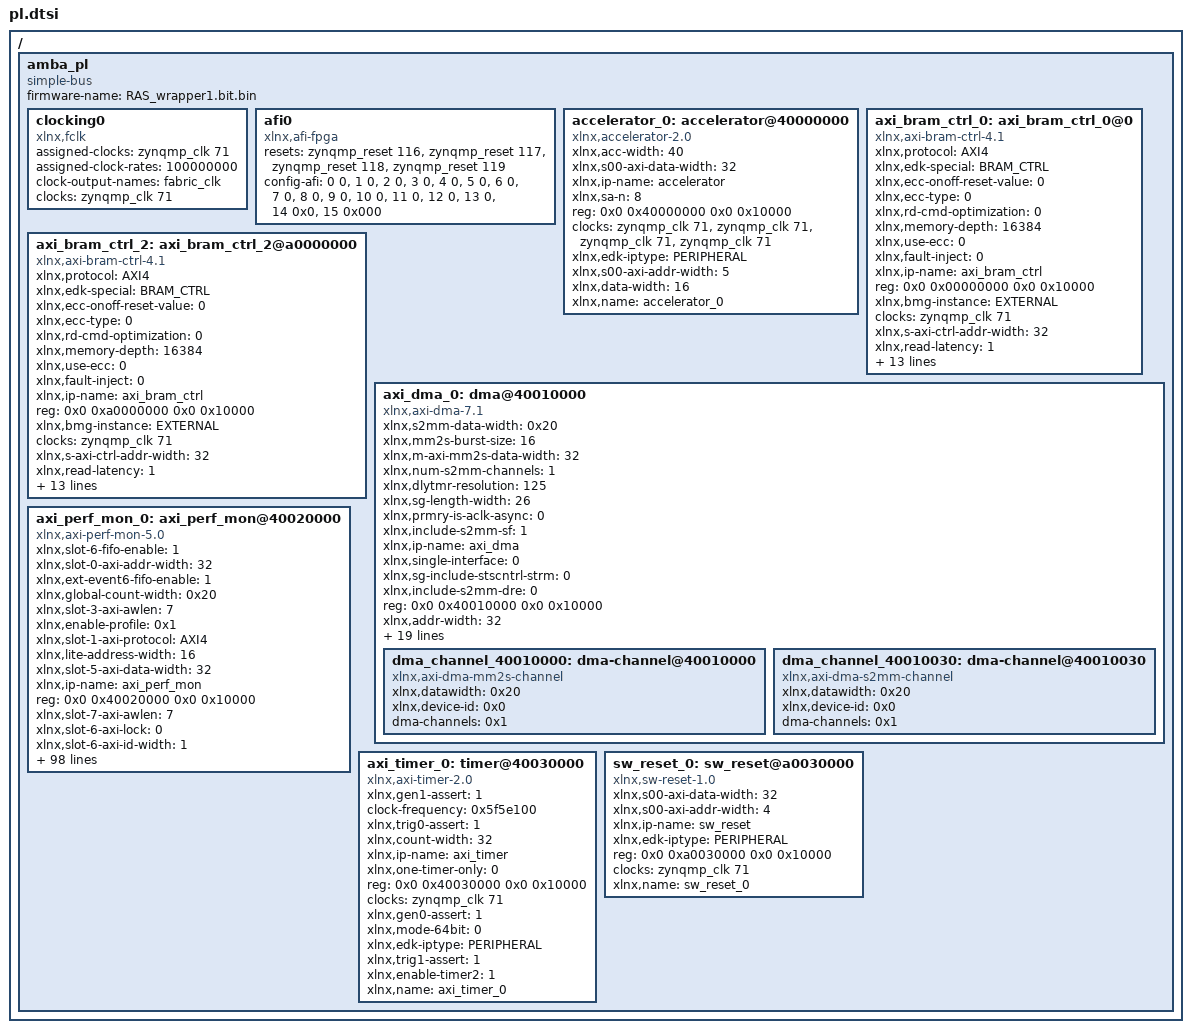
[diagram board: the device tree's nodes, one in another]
/ {
	amba_pl: amba_pl {
		ranges;
		compatible = "simple-bus";
		#address-cells = <2>;
		#size-cells = <2>;
		firmware-name = "RAS_wrapper1.bit.bin";
		clocking0: clocking0 {
			compatible = "xlnx,fclk";
			status = "okay";
			assigned-clocks = <&zynqmp_clk 71>;
			assigned-clock-rates = <100000000>;
			#clock-cells = <0>;
			clock-output-names = "fabric_clk";
			clocks = <&zynqmp_clk 71>;
		};
		afi0: afi0 {
			status = "okay";
			compatible = "xlnx,afi-fpga";
			resets = <&zynqmp_reset 116>, <&zynqmp_reset 117>, <&zynqmp_reset 118>, <&zynqmp_reset 119>;
			config-afi = < 0 0>, <1 0>, <2 0>, <3 0>, <4 0>, <5 0>, <6 0>, <7 0>, <8 0>, <9 0>, <10 0>, <11 0>, <12 0>, <13 0>, <14 0x0>, <15 0x000>;
		};
		accelerator_0: accelerator@40000000 {
			compatible = "xlnx,accelerator-2.0";
			xlnx,acc-width = <40>;
			xlnx,s00-axi-data-width = <32>;
			xlnx,ip-name = "accelerator";
			xlnx,sa-n = <8>;
			reg = <0x0 0x40000000 0x0 0x10000>;
			clocks = <&zynqmp_clk 71>, <&zynqmp_clk 71>, <&zynqmp_clk 71>, <&zynqmp_clk 71>;
			xlnx,edk-iptype = "PERIPHERAL";
			status = "okay";
			xlnx,s00-axi-addr-width = <5>;
			xlnx,data-width = <16>;
			clock-names = "m00_axis_aclk" , "m_axi_dma_aclk" , "s00_axi_aclk" , "s00_axis_aclk";
			xlnx,name = "accelerator_0";
		};
		axi_bram_ctrl_0: axi_bram_ctrl_0@0 {
			xlnx,protocol = "AXI4";
			xlnx,edk-special = "BRAM_CTRL";
			compatible = "xlnx,axi-bram-ctrl-4.1" , "xlnx,axi-bram-ctrl";
			xlnx,ecc-onoff-reset-value = <0>;
			xlnx,ecc-type = <0>;
			xlnx,rd-cmd-optimization = <0>;
			xlnx,memory-depth = <16384>;
			xlnx,use-ecc = <0>;
			xlnx,fault-inject = <0>;
			xlnx,ip-name = "axi_bram_ctrl";
			reg = <0x0 0x00000000 0x0 0x10000>;
			xlnx,bmg-instance = "EXTERNAL";
			clocks = <&zynqmp_clk 71>;
			xlnx,s-axi-ctrl-addr-width = <32>;
			xlnx,read-latency = <1>;
			xlnx,id-width = <0>;
			xlnx,s-axi-supports-narrow-burst = <0>;
			xlnx,supports-narrow-burst = <0>;
			xlnx,single-port-bram = <1>;
			xlnx,ecc = <0>;
			xlnx,edk-iptype = "PERIPHERAL";
			status = "okay";
			clock-names = "s_axi_aclk";
			xlnx,data-width = <32>;
			xlnx,bram-addr-width = <14>;
			xlnx,bram-inst-mode = "EXTERNAL";
			xlnx,s-axi-ctrl-data-width = <32>;
			xlnx,mem-depth = <16384>;
			xlnx,s-axi-id-width = <1>;
			xlnx,name = "axi_bram_ctrl_0";
		};
		axi_bram_ctrl_2: axi_bram_ctrl_2@a0000000 {
			xlnx,protocol = "AXI4";
			xlnx,edk-special = "BRAM_CTRL";
			compatible = "xlnx,axi-bram-ctrl-4.1" , "xlnx,axi-bram-ctrl";
			xlnx,ecc-onoff-reset-value = <0>;
			xlnx,ecc-type = <0>;
			xlnx,rd-cmd-optimization = <0>;
			xlnx,memory-depth = <16384>;
			xlnx,use-ecc = <0>;
			xlnx,fault-inject = <0>;
			xlnx,ip-name = "axi_bram_ctrl";
			reg = <0x0 0xa0000000 0x0 0x10000>;
			xlnx,bmg-instance = "EXTERNAL";
			clocks = <&zynqmp_clk 71>;
			xlnx,s-axi-ctrl-addr-width = <32>;
			xlnx,read-latency = <1>;
			xlnx,id-width = <0>;
			xlnx,s-axi-supports-narrow-burst = <0>;
			xlnx,supports-narrow-burst = <0>;
			xlnx,single-port-bram = <1>;
			xlnx,ecc = <0>;
			xlnx,edk-iptype = "PERIPHERAL";
			status = "okay";
			clock-names = "s_axi_aclk";
			xlnx,data-width = <32>;
			xlnx,bram-addr-width = <14>;
			xlnx,bram-inst-mode = "EXTERNAL";
			xlnx,s-axi-ctrl-data-width = <32>;
			xlnx,mem-depth = <16384>;
			xlnx,s-axi-id-width = <1>;
			xlnx,name = "axi_bram_ctrl_2";
		};
		axi_dma_0: dma@40010000 {
			compatible = "xlnx,axi-dma-7.1" , "xlnx,axi-dma-1.00.a";
			xlnx,s2mm-data-width = <0x20>;
			xlnx,mm2s-burst-size = <16>;
			xlnx,m-axi-mm2s-data-width = <32>;
			xlnx,num-s2mm-channels = <1>;
			xlnx,dlytmr-resolution = <125>;
			xlnx,sg-length-width = <26>;
			xlnx,prmry-is-aclk-async = <0>;
			xlnx,include-s2mm-sf = <1>;
			#dma-cells = <1>;
			xlnx,ip-name = "axi_dma";
			xlnx,single-interface = <0>;
			xlnx,sg-include-stscntrl-strm = <0>;
			xlnx,include-s2mm-dre = <0>;
			reg = <0x0 0x40010000 0x0 0x10000>;
			xlnx,addr-width = <32>;
			xlnx,include-s2mm = <1>;
			clocks = <&zynqmp_clk 71>, <&zynqmp_clk 71>, <&zynqmp_clk 71>;
			xlnx,s-axis-s2mm-tdata-width = <32>;
			xlnx,micro-dma = <0>;
			xlnx,increase-throughput = <0>;
			xlnx,mm2s-data-width = <0x20>;
			xlnx,addrwidth = <0x20>;
			xlnx,sg-use-stsapp-length = <0>;
			xlnx,m-axis-mm2s-tdata-width = <32>;
			xlnx,edk-iptype = "PERIPHERAL";
			xlnx,s2mm-burst-size = <16>;
			xlnx,m-axi-s2mm-data-width = <32>;
			xlnx,num-mm2s-channels = <1>;
			xlnx,enable-multi-channel = <0>;
			status = "okay";
			xlnx,include-mm2s-sf = <1>;
			clock-names = "m_axi_mm2s_aclk" , "m_axi_s2mm_aclk" , "s_axi_lite_aclk";
			xlnx,include-mm2s = <1>;
			xlnx,include-mm2s-dre = <0>;
			xlnx,name = "axi_dma_0";
			dma_channel_40010000: dma-channel@40010000 {
				xlnx,datawidth = <0x20>;
				xlnx,device-id = <0x0>;
				compatible = "xlnx,axi-dma-mm2s-channel";
				dma-channels = <0x1>;
			};
			dma_channel_40010030: dma-channel@40010030 {
				xlnx,datawidth = <0x20>;
				xlnx,device-id = <0x0>;
				compatible = "xlnx,axi-dma-s2mm-channel";
				dma-channels = <0x1>;
			};
		};
		axi_perf_mon_0: axi_perf_mon@40020000 {
			xlnx,slot-6-fifo-enable = <1>;
			xlnx,slot-0-axi-addr-width = <32>;
			xlnx,ext-event6-fifo-enable = <1>;
			xlnx,global-count-width = <0x20>;
			xlnx,slot-3-axi-awlen = <7>;
			xlnx,enable-profile = <0x1>;
			xlnx,slot-1-axi-protocol = "AXI4";
			xlnx,lite-address-width = <16>;
			xlnx,slot-5-axi-data-width = <32>;
			xlnx,ip-name = "axi_perf_mon";
			reg = <0x0 0x40020000 0x0 0x10000>;
			xlnx,slot-7-axi-awlen = <7>;
			xlnx,slot-6-axi-lock = <0>;
			xlnx,slot-6-axi-id-width = <1>;
			xlnx,slot-4-axi-data-width = <32>;
			xlnx,num-monitor-slots = <0x2>;
			xlnx,reg-all-monitor-signals = <0>;
			xlnx,slot-3-axi-id-width = <1>;
			xlnx,fifo-axis-sync = <0>;
			xlnx,s-axi-id-width = <1>;
			xlnx,slot-7-axi-addr-width = <32>;
			xlnx,slot-0-axi-awlen = <7>;
			compatible = "xlnx,axi-perf-mon-5.0" , "xlnx,axi-perf-monitor";
			xlnx,slot-7-axi-lock = <0>;
			xlnx,slot-6-axi-protocol = "AXI4";
			xlnx,en-last-write-flag = <1>;
			xlnx,slot-0-axi-lock = <0>;
			xlnx,axi4lite-core-clk-async = <0>;
			xlnx,slot-3-axi-data-width = <32>;
			xlnx,slot-0-axi-id-width = <1>;
			xlnx,slot-4-axi-awlen = <7>;
			xlnx,slot-3-axi-protocol = "AXI4";
			xlnx,slot-6-axi-addr-width = <32>;
			xlnx,fifo-axis-tid-width = <1>;
			xlnx,en-ext-events-flag = <0>;
			xlnx,enable-advanced = <0>;
			xlnx,num-of-counters = <0x1>;
			xlnx,en-rd-add-flag = <1>;
			xlnx,slot-2-axi-data-width = <32>;
			xlnx,show-axi-len = <0>;
			xlnx,slot-1-fifo-enable = <0>;
			xlnx,slot-1-axi-lock = <0>;
			xlnx,slot-0-axi-protocol = "AXI4";
			status = "okay";
			xlnx,ext-event1-fifo-enable = <1>;
			xlnx,enable-ext-events = <0>;
			xlnx,counter-load-value = <0x0>;
			xlnx,slot-3-fifo-enable = <1>;
			xlnx,en-first-write-flag = <1>;
			xlnx,slot-5-axi-addr-width = <32>;
			xlnx,ext-event3-fifo-enable = <1>;
			xlnx,slot-5-fifo-enable = <1>;
			xlnx,name = "axi_perf_mon_0";
			xlnx,edk-special = "MONITOR";
			xlnx,slot-5-axi-id-width = <1>;
			xlnx,en-sw-reg-wr-flag = <0>;
			xlnx,ext-event5-fifo-enable = <1>;
			xlnx,slot-7-fifo-enable = <1>;
			xlnx,slot-1-axi-data-width = <32>;
			xlnx,slot-1-axi-awlen = <7>;
			xlnx,ext-event7-fifo-enable = <1>;
			xlnx,show-axi-ids = <0>;
			xlnx,slot-2-axi-lock = <0>;
			xlnx,en-axi-debug = <0>;
			xlnx,support-id-reflection = <0>;
			xlnx,slot-5-axi-awlen = <7>;
			xlnx,slot-4-axi-addr-width = <32>;
			xlnx,slot-2-axi-id-width = <1>;
			xlnx,metric-count-scale = <0x1>;
			xlnx,en-first-read-flag = <1>;
			clocks = <&zynqmp_clk 71>, <&zynqmp_clk 71>, <&zynqmp_clk 71>, <&zynqmp_clk 71>;
			xlnx,metrics-sample-count-width = <0x20>;
			xlnx,slot-5-axi-protocol = "AXI4";
			xlnx,slot-0-axi-data-width = <32>;
			xlnx,enable-trace = <0x0>;
			xlnx,edk-iptype = "MONITOR";
			xlnx,en-all-trace = <1>;
			xlnx,slot-3-axi-addr-width = <32>;
			xlnx,en-wr-add-flag = <1>;
			xlnx,fifo-axis-tdata-width = <56>;
			clock-names = "core_aclk" , "s_axi_aclk" , "slot_0_axi_aclk" , "slot_1_axi_aclk";
			xlnx,slot-3-axi-lock = <0>;
			xlnx,slot-2-axi-protocol = "AXI4";
			xlnx,slot-7-axi-id-width = <1>;
			xlnx,slot-2-axi-awlen = <7>;
			xlnx,slot-2-axi-addr-width = <32>;
			xlnx,enable-event-log = <0x0>;
			xlnx,en-response-flag = <1>;
			xlnx,slot-6-axi-awlen = <7>;
			xlnx,slot-4-axi-lock = <0>;
			xlnx,slot-7-axi-data-width = <32>;
			xlnx,slot-4-axi-id-width = <1>;
			xlnx,log-data-offld = <0>;
			xlnx,have-sampled-metric-cnt = <0x1>;
			xlnx,slot-7-axi-protocol = "AXI4";
			xlnx,slot-1-axi-addr-width = <32>;
			xlnx,slot-0-fifo-enable = <0>;
			xlnx,en-last-read-flag = <1>;
			xlnx,en-trigger = <0>;
			xlnx,enable-event-count = <0x0>;
			xlnx,axis-dwidth-round-to-32 = <64>;
			xlnx,ext-event0-fifo-enable = <1>;
			xlnx,slot-2-fifo-enable = <1>;
			xlnx,slot-1-axi-id-width = <1>;
			xlnx,ext-event2-fifo-enable = <1>;
			xlnx,metric-count-width = <0x20>;
			xlnx,slot-6-axi-data-width = <32>;
			xlnx,slot-4-fifo-enable = <1>;
			xlnx,fifo-axis-depth = <32>;
			xlnx,s-axi-offld-id-width = <1>;
			xlnx,enable-ext-triggers = <1>;
			xlnx,slot-5-axi-lock = <0>;
			xlnx,slot-4-axi-protocol = "AXI4";
			xlnx,ext-event4-fifo-enable = <1>;
		};
		axi_timer_0: timer@40030000 {
			compatible = "xlnx,axi-timer-2.0" , "xlnx,xps-timer-1.00.a";
			xlnx,gen1-assert = <1>;
			clock-frequency = <0x5f5e100>;
			xlnx,trig0-assert = <1>;
			xlnx,count-width = <32>;
			xlnx,ip-name = "axi_timer";
			xlnx,one-timer-only = <0>;
			reg = <0x0 0x40030000 0x0 0x10000>;
			clocks = <&zynqmp_clk 71>;
			xlnx,gen0-assert = <1>;
			xlnx,mode-64bit = <0>;
			xlnx,edk-iptype = "PERIPHERAL";
			status = "okay";
			xlnx,trig1-assert = <1>;
			clock-names = "s_axi_aclk";
			xlnx,enable-timer2 = <1>;
			xlnx,name = "axi_timer_0";
		};
		sw_reset_0: sw_reset@a0030000 {
			xlnx,s00-axi-data-width = <32>;
			compatible = "xlnx,sw-reset-1.0";
			status = "okay";
			clock-names = "s00_axi_aclk";
			xlnx,s00-axi-addr-width = <4>;
			xlnx,ip-name = "sw_reset";
			xlnx,edk-iptype = "PERIPHERAL";
			reg = <0x0 0xa0030000 0x0 0x10000>;
			clocks = <&zynqmp_clk 71>;
			xlnx,name = "sw_reset_0";
		};
	};
};
